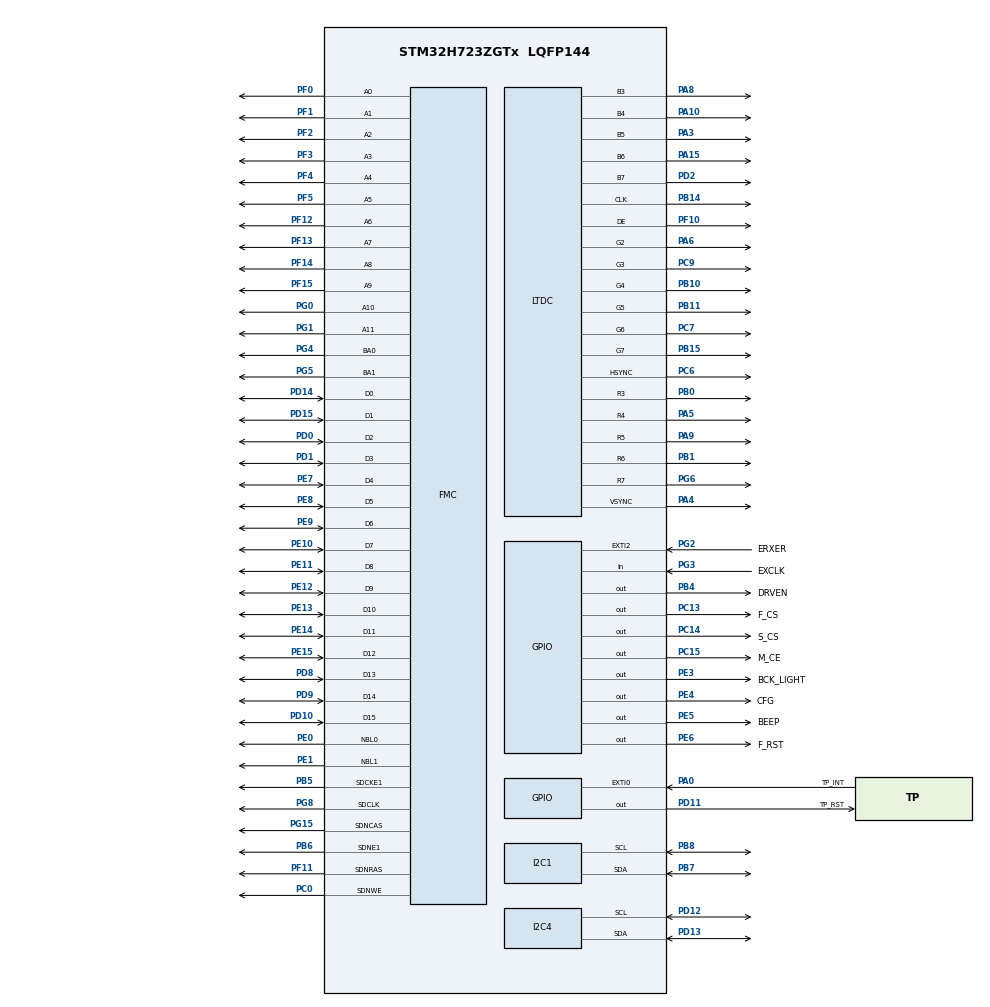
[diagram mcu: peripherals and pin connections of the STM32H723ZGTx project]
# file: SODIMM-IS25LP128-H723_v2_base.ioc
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CORTEX_M7.BaseAddress_S-Cortex_Memory_Protection_Unit_Region1_Settings_S=0x0
CORTEX_M7.BaseAddress_Spec=0xD0000000
CORTEX_M7.Enable_S-Cortex_Memory_Protection_Unit_Region1_Settings_S=__NULL
CORTEX_M7.IsCacheable_Spec=MPU_ACCESS_CACHEABLE
CORTEX_M7.IsShareable_Spec=MPU_ACCESS_NOT_SHAREABLE
CORTEX_M7.Size_S-Cortex_Memory_Protection_Unit_Region1_Settings_S=MPU_REGION_SIZE_8MB
CORTEX_M7.Size_Spec=MPU_REGION_SIZE_8MB
CORTEX_M7.SubRegionDisable_Spec=0x00
CORTEX_M7.default_mode_Activation=0
FMC.BankMapConfig=FMC_SWAPBMAP_DISABLE
FMC.CASLatency1=FMC_SDRAM_CAS_LATENCY_2
FMC.ExitSelfRefreshDelay1=7
FMC.LoadToActiveDelay1=2
FMC.RCDDelay1=2
FMC.RPDelay1=2
FMC.ReadBurst1=FMC_SDRAM_RBURST_ENABLE
FMC.ReadPipeDelay1=FMC_SDRAM_RPIPE_DELAY_2
FMC.RowCycleDelay1=6
FMC.SDClockPeriod1=FMC_SDRAM_CLOCK_PERIOD_2
FMC.SelfRefreshTime1=5
FMC.WriteRecoveryTime1=3
FREERTOS.Tasks01=defaultTask,0,128,StartDefaultTask,Default,NULL,Dynamic,NULL,NULL
I2C1.Timing=0x00000E14
I2C4.Timing=0x00000E14
LTDC.ActiveH=480
LTDC.ActiveW=800
LTDC.Alpha0_L0=0
LTDC.Alpha_L0=255
LTDC.Blue=0
LTDC.Blue_L0=0
LTDC.FBStartAdress_L0=0xD0000000
LTDC.Green=0
LTDC.Green_L0=0
LTDC.HBP=10
LTDC.HFP=10
LTDC.HSPolarity=LTDC_HSPOLARITY_AL
LTDC.HSync=10
LTDC.ImageHeight_L0=480
LTDC.ImageWidth_L0=800
LTDC.Layers=0
LTDC.PixelFormat_L0=LTDC_PIXEL_FORMAT_RGB565
LTDC.Red=0
LTDC.Red_L0=0
LTDC.VBP=2
LTDC.VFP=4
LTDC.VSync=2
LTDC.WindowX0_L0=0
LTDC.WindowX1_L0=800
LTDC.WindowY1_L0=480
Mcu.Family=STM32H7
Mcu.Name=STM32H723ZGTx
Mcu.Package=LQFP144
NVIC.LTDC_ER_IRQn=true\:5\:0\:false\:false\:true\:true\:true\:true\:true
NVIC.LTDC_IRQn=true\:5\:0\:false\:false\:true\:true\:true\:true\:true
NVIC.PriorityGroup=NVIC_PRIORITYGROUP_4
NVIC.TIM17_IRQn=true\:15\:0\:false\:false\:true\:false\:false\:true\:true
NVIC.TimeBase=TIM17_IRQn
NVIC.TimeBaseIP=TIM17
PA0.GPIO_Label=TP_INT
PA0.Signal=GPXTI0
PA10.Mode=RGB565
PA10.Signal=LTDC_B4
PA13(JTMS/SWDIO).Mode=Serial_Wire
PA13(JTMS/SWDIO).Signal=DEBUG_JTMS-SWDIO
PA14(JTCK/SWCLK).Mode=Serial_Wire
PA14(JTCK/SWCLK).Signal=DEBUG_JTCK-SWCLK
PA15(JTDI).Mode=RGB565
PA15(JTDI).Signal=LTDC_B6
PA3.Mode=RGB565
PA3.Signal=LTDC_B5
PA4.GPIO_Speed=GPIO_SPEED_FREQ_VERY_HIGH
PA4.Mode=RGB565
PA4.Signal=LTDC_VSYNC
PA5.Mode=RGB565
PA5.Signal=LTDC_R4
PA6.Mode=RGB565
PA6.Signal=LTDC_G2
PA8.Mode=RGB565
PA8.Signal=LTDC_B3
PA9.Mode=RGB565
PA9.Signal=LTDC_R5
PB0.Mode=RGB565
PB0.Signal=LTDC_R3
PB1.Mode=RGB565
PB1.Signal=LTDC_R6
PB10.Mode=RGB565
PB10.Signal=LTDC_G4
PB11.Mode=RGB565
PB11.Signal=LTDC_G5
PB14.GPIO_Speed=GPIO_SPEED_FREQ_VERY_HIGH
PB14.Mode=RGB565
PB14.Signal=LTDC_CLK
PB15.Mode=RGB565
PB15.Signal=LTDC_G7
PB4(NJTRST).GPIO_Label=DRVEN
PB4(NJTRST).Signal=GPIO_Output
PB5.Mode=SdramChipSelect2_1
PB5.Signal=FMC_SDCKE1
PB6.Mode=SdramChipSelect2_1
PB6.Signal=FMC_SDNE1
PB7.Mode=I2C
PB7.Signal=I2C1_SDA
PB8.Mode=I2C
PB8.Signal=I2C1_SCL
PC0.Signal=FMC_SDNWE
PC13.GPIO_Label=F_CS
PC13.Signal=GPIO_Output
PC14-OSC32_IN.GPIO_Label=S_CS
PC14-OSC32_IN.Signal=GPIO_Output
PC15-OSC32_OUT.GPIO_Label=M_CE
PC15-OSC32_OUT.Signal=GPIO_Output
PC6.GPIO_Speed=GPIO_SPEED_FREQ_VERY_HIGH
PC6.Mode=RGB565
PC6.Signal=LTDC_HSYNC
PC7.Mode=RGB565
PC7.Signal=LTDC_G6
PC9.Mode=RGB565
PC9.Signal=LTDC_G3
PD0.Signal=FMC_D2_DA2
PD1.Signal=FMC_D3_DA3
PD10.Signal=FMC_D15_DA15
PD11.GPIO_Label=TP_RST
PD11.Signal=GPIO_Output
PD12.Mode=I2C
PD12.Signal=I2C4_SCL
PD13.Mode=I2C
PD13.Signal=I2C4_SDA
PD14.Signal=FMC_D0_DA0
PD15.Signal=FMC_D1_DA1
PD2.Mode=RGB565
PD2.Signal=LTDC_B7
PD8.Signal=FMC_D13_DA13
PD9.Signal=FMC_D14_DA14
PE0.Signal=FMC_NBL0
PE1.Signal=FMC_NBL1
PE10.Signal=FMC_D7_DA7
PE11.Signal=FMC_D8_DA8
PE12.Signal=FMC_D9_DA9
PE13.Signal=FMC_D10_DA10
PE14.Signal=FMC_D11_DA11
PE15.Signal=FMC_D12_DA12
PE3.GPIO_Label=BCK_LIGHT
PE3.PinState=GPIO_PIN_SET
PE3.Signal=GPIO_Output
PE4.GPIO_Label=CFG
PE4.Signal=GPIO_Output
PE5.GPIO_Label=BEEP
PE5.Signal=GPIO_Output
PE6.GPIO_Label=F_RST
PE6.Signal=GPIO_Output
PE7.Signal=FMC_D4_DA4
PE8.Signal=FMC_D5_DA5
PE9.Signal=FMC_D6_DA6
PF0.Signal=FMC_A0
PF1.Signal=FMC_A1
PF10.Mode=RGB565
PF10.Signal=LTDC_DE
PF11.Signal=FMC_SDNRAS
PF12.Signal=FMC_A6
PF13.Signal=FMC_A7
PF14.Signal=FMC_A8
PF15.Signal=FMC_A9
PF2.Signal=FMC_A2
PF3.Signal=FMC_A3
PF4.Signal=FMC_A4
PF5.Signal=FMC_A5
PG0.Signal=FMC_A10
PG1.Signal=FMC_A11
PG15.Signal=FMC_SDNCAS
PG2.GPIO_Label=ERXER
PG2.Signal=GPXTI2
PG3.GPIO_Label=EXCLK
PG3.Signal=GPIO_Input
PG4.Signal=FMC_A14_BA0
PG5.Signal=FMC_A15_BA1
PG6.Mode=RGB565
PG6.Signal=LTDC_R7
PG8.Signal=FMC_SDCLK
PH0-OSC_IN.Mode=HSE-External-Oscillator
PH0-OSC_IN.Signal=RCC_OSC_IN
PH1-OSC_OUT.Mode=HSE-External-Oscillator
PH1-OSC_OUT.Signal=RCC_OSC_OUT
ProjectManager.HeapSize=0x200
ProjectManager.StackSize=0x400
ProjectManager.TargetToolchain=STM32CubeIDE
RCC.ADCFreq_Value=200000000
RCC.APB1Freq_Value=137000000
RCC.APB2Freq_Value=137000000
RCC.APB3Freq_Value=137000000
RCC.APB4Freq_Value=137000000
RCC.CKPERSourceSelection=RCC_CLKPSOURCE_HSE
RCC.CortexFreq_Value=548000000
RCC.D1PPRE=RCC_APB3_DIV2
RCC.D2PPRE1=RCC_APB1_DIV2
RCC.D2PPRE2=RCC_APB2_DIV2
RCC.D3PPRE=RCC_APB4_DIV2
RCC.DIVM1=1
RCC.DIVM2=2
RCC.DIVM3=1
RCC.DIVN1=137
RCC.DIVN2=200
RCC.DIVN3=24
RCC.DIVP1=1
RCC.DIVP3=4
RCC.DIVQ1=5
RCC.DIVQ2=20
RCC.DIVQ3=8
RCC.DIVR1=1
RCC.DIVR3=3
RCC.FDCANCLockSelection=RCC_FDCANCLKSOURCE_PLL2
RCC.FMCCLockSelection=RCC_FMCCLKSOURCE_PLL2
RCC.HCLKFreq_Value=274000000
RCC.HPRE=RCC_HCLK_DIV2
RCC.HSE_VALUE=8000000
RCC.I2C123CLockSelection=RCC_I2C1235CLKSOURCE_CSI
RCC.I2C4CLockSelection=RCC_I2C4CLKSOURCE_CSI
RCC.PLL2FRACN=0
RCC.PLL3FRACN=0
RCC.PLLFRACN=0
RCC.PLLSourceVirtual=RCC_PLLSOURCE_CSI
RCC.QSPICLockSelection=RCC_OSPICLKSOURCE_PLL
RCC.SPI123CLockSelection=RCC_SPI123CLKSOURCE_CLKP
RCC.SYSCLKFreq_VALUE=548000000
RCC.SYSCLKSource=RCC_SYSCLKSOURCE_PLLCLK
RCC.SupplySource=PWR_LDO_SUPPLY
RCC.USART234578CLockSelection=RCC_USART234578CLKSOURCE_HSI
RCC.USBCLockSelection=RCC_USBCLKSOURCE_HSI48
RCC.USBFreq_Value=48000000
RCC.VDD_VALUE=3.2
SH.FMC_A0.0=FMC_A0,12b-sda1
SH.FMC_A1.0=FMC_A1,12b-sda1
SH.FMC_A10.0=FMC_A10,12b-sda1
SH.FMC_A11.0=FMC_A11,12b-sda1
SH.FMC_A14_BA0.0=FMC_BA0,FourSdramBanks1
SH.FMC_A15_BA1.0=FMC_BA1,FourSdramBanks1
SH.FMC_A2.0=FMC_A2,12b-sda1
SH.FMC_A3.0=FMC_A3,12b-sda1
SH.FMC_A4.0=FMC_A4,12b-sda1
SH.FMC_A5.0=FMC_A5,12b-sda1
SH.FMC_A6.0=FMC_A6,12b-sda1
SH.FMC_A7.0=FMC_A7,12b-sda1
SH.FMC_A8.0=FMC_A8,12b-sda1
SH.FMC_A9.0=FMC_A9,12b-sda1
SH.FMC_D0_DA0.0=FMC_D0,sd-16b-d1
SH.FMC_D10_DA10.0=FMC_D10,sd-16b-d1
SH.FMC_D11_DA11.0=FMC_D11,sd-16b-d1
SH.FMC_D12_DA12.0=FMC_D12,sd-16b-d1
SH.FMC_D13_DA13.0=FMC_D13,sd-16b-d1
SH.FMC_D14_DA14.0=FMC_D14,sd-16b-d1
SH.FMC_D15_DA15.0=FMC_D15,sd-16b-d1
SH.FMC_D1_DA1.0=FMC_D1,sd-16b-d1
SH.FMC_D2_DA2.0=FMC_D2,sd-16b-d1
SH.FMC_D3_DA3.0=FMC_D3,sd-16b-d1
SH.FMC_D4_DA4.0=FMC_D4,sd-16b-d1
SH.FMC_D5_DA5.0=FMC_D5,sd-16b-d1
SH.FMC_D6_DA6.0=FMC_D6,sd-16b-d1
SH.FMC_D7_DA7.0=FMC_D7,sd-16b-d1
SH.FMC_D8_DA8.0=FMC_D8,sd-16b-d1
SH.FMC_D9_DA9.0=FMC_D9,sd-16b-d1
SH.FMC_NBL0.0=FMC_NBL0,Sd2ByteEnable1
SH.FMC_NBL1.0=FMC_NBL1,Sd2ByteEnable1
SH.FMC_SDCLK.0=FMC_SDCLK,12b-sda1
SH.FMC_SDNCAS.0=FMC_SDNCAS,12b-sda1
SH.FMC_SDNRAS.0=FMC_SDNRAS,12b-sda1
SH.FMC_SDNWE.0=FMC_SDNWE,12b-sda1
STMicroelectronics.X-CUBE-TOUCHGFX.4.20.0.ApplicationCcGraphicsJjApplication=TouchGFXOoGenerator
STMicroelectronics.X-CUBE-TOUCHGFX.4.20.0.tgfx_address1=0xD0000000
STMicroelectronics.X-CUBE-TOUCHGFX.4.20.0.tgfx_address2=0xD0010000
STMicroelectronics.X-CUBE-TOUCHGFX.4.20.0.tgfx_buffering_strategy=Single
STMicroelectronics.X-CUBE-TOUCHGFX.4.20.0.tgfx_custom_height=480
STMicroelectronics.X-CUBE-TOUCHGFX.4.20.0.tgfx_display_interface=disp_ltdc
STMicroelectronics.X-CUBE-TOUCHGFX.4.20.0.tgfx_hardware_accelerator=dma_none
STMicroelectronics.X-CUBE-TOUCHGFX.4.20.0.tgfx_location=By Address
STMicroelectronics.X-CUBE-TOUCHGFX.4.20.0.tgfx_vsync=vsync_ltdc
STMicroelectronics.X-CUBE-TOUCHGFX.4.20.0_IsPackSelfContextualization=true
VP_CRC_VS_CRC.Mode=CRC_Activate
VP_FREERTOS_VS_CMSIS_V1.Mode=CMSIS_V1
VP_STMicroelectronics.X-CUBE-TOUCHGFX_VS_GraphicsJjApplication_4.20.0.Mode=GraphicsJjApplication
VP_SYS_VS_tim17.Mode=TIM17
board=custom

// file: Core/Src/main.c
/* USER CODE BEGIN Header */
/**
  ******************************************************************************
  * @file           : main.c
  * @brief          : Main program body
  ******************************************************************************
  * @attention
  *
  * Copyright (c) 2022 STMicroelectronics.
  * All rights reserved.
  *
  * This software is licensed under terms that can be found in the LICENSE file
  * in the root directory of this software component.
  * If no LICENSE file comes with this software, it is provided AS-IS.
  *
  ******************************************************************************
  */
/* USER CODE END Header */
#include "main.h"
#include "cmsis_os.h"
#include "app_touchgfx.h"

/* USER CODE BEGIN Includes */
//uint16_t* frame_buffer = (uint16_t*) 0xD0000000;

#define SDRAM_BANK_ADDR                 ((uint32_t)0xD0000000)

/* #define SDRAM_MEMORY_WIDTH            FMC_SDMemory_Width_8b  */
#define SDRAM_MEMORY_WIDTH            FMC_SDMemory_Width_16b
//uint32_t FrontBuffer = SDRAM_BANK_ADDR;
volatile uint16_t temp[10];
//__attribute__((section(".sdram"))) uint32_t framebuffer[];

#define SDRAM_MODEREG_BURST_LENGTH_1             ((uint16_t)0x0000)
#define SDRAM_MODEREG_BURST_LENGTH_2             ((uint16_t)0x0001)
#define SDRAM_MODEREG_BURST_LENGTH_4             ((uint16_t)0x0002)
#define SDRAM_MODEREG_BURST_LENGTH_8             ((uint16_t)0x0003)
#define SDRAM_MODEREG_BURST_TYPE_SEQUENTIAL      ((uint16_t)0x0000)
#define SDRAM_MODEREG_BURST_TYPE_INTERLEAVED     ((uint16_t)0x0008)
#define SDRAM_MODEREG_CAS_LATENCY_2              ((uint16_t)0x0020)
#define SDRAM_MODEREG_CAS_LATENCY_3              ((uint16_t)0x0030)
#define SDRAM_MODEREG_OPERATING_MODE_STANDARD    ((uint16_t)0x0000)
#define SDRAM_MODEREG_WRITEBURST_MODE_PROGRAMMED ((uint16_t)0x0000)
#define SDRAM_MODEREG_WRITEBURST_MODE_SINGLE     ((uint16_t)0x0200)

#define SDRAM_REFRESH_COUNT                   	 ((uint32_t)4096)

/* USER CODE END Includes */

/* USER CODE BEGIN PTD */

	// Assign SDRAM address to pointer

/* USER CODE END PTD */

CRC_HandleTypeDef hcrc;

I2C_HandleTypeDef hi2c1;
I2C_HandleTypeDef hi2c4;

LTDC_HandleTypeDef hltdc;

SDRAM_HandleTypeDef hsdram1;

osThreadId defaultTaskHandle;

void SystemClock_Config(void);
static void MX_GPIO_Init(void);
static void MX_FMC_Init(void);
static void MX_I2C1_Init(void);
static void MX_I2C4_Init(void);
static void MX_LTDC_Init(void);
static void MX_CRC_Init(void);
void StartDefaultTask(void const * argument);

int main(void)
{
  /* USER CODE BEGIN 1 */

	  MPU->RNR = 1;

	  //External Ram base address
	  MPU->RBAR = 0xD0000000;

	  //XN=Disabled, AP=Full Access, TEX=Level 2, S=Not Shareable, C=Not Cacheable, B=Not bufferable, SRB=Disabled, Size=8MB, Enable=1
	  MPU->RASR = (1 << MPU_RASR_XN_Pos) |
	         (3 << MPU_RASR_AP_Pos) |
	        (2 << MPU_RASR_TEX_Pos) |
	        (0 << MPU_RASR_S_Pos) |
	        (0 << MPU_RASR_C_Pos) |
	        (0 << MPU_RASR_B_Pos) |
	        (1 << MPU_RASR_SRD_Pos) |
	        (0x16 << MPU_RASR_SIZE_Pos) |
	        (1 << MPU_RASR_ENABLE_Pos);

  /* USER CODE END 1 */

  /* MCU Configuration--------------------------------------------------------*/

  /* Reset of all peripherals, Initializes the Flash interface and the Systick. */
  HAL_Init();

  /* Configure the system clock */
  SystemClock_Config();

  /* Initialize all configured peripherals */
  MX_GPIO_Init();
  MX_FMC_Init();
  MX_I2C1_Init();
  MX_I2C4_Init();
  MX_LTDC_Init();
  MX_CRC_Init();
  MX_TouchGFX_Init();
  /* Call PreOsInit function */
  MX_TouchGFX_PreOSInit();

  /* Create the thread(s) */
  /* definition and creation of defaultTask */
  osThreadDef(defaultTask, StartDefaultTask, osPriorityNormal, 0, 128);
  defaultTaskHandle = osThreadCreate(osThread(defaultTask), NULL);

  /* Start scheduler */
  osKernelStart();

  /* We should never get here as control is now taken by the scheduler */
  /* Infinite loop */
  while (1)
  {

  }
}

void SystemClock_Config(void)
{
  RCC_OscInitTypeDef RCC_OscInitStruct = {0};
  RCC_ClkInitTypeDef RCC_ClkInitStruct = {0};

  /** Supply configuration update enable
  */
  HAL_PWREx_ConfigSupply(PWR_LDO_SUPPLY);

  /** Configure the main internal regulator output voltage
  */
  __HAL_PWR_VOLTAGESCALING_CONFIG(PWR_REGULATOR_VOLTAGE_SCALE0);

  while(!__HAL_PWR_GET_FLAG(PWR_FLAG_VOSRDY)) {}

  /** Macro to configure the PLL clock source
  */
  __HAL_RCC_PLL_PLLSOURCE_CONFIG(RCC_PLLSOURCE_CSI);

  /** Initializes the RCC Oscillators according to the specified parameters
  * in the RCC_OscInitTypeDef structure.
  */
  RCC_OscInitStruct.OscillatorType = RCC_OSCILLATORTYPE_CSI;
  RCC_OscInitStruct.CSIState = RCC_CSI_ON;
  RCC_OscInitStruct.CSICalibrationValue = 16;
  RCC_OscInitStruct.PLL.PLLState = RCC_PLL_ON;
  RCC_OscInitStruct.PLL.PLLSource = RCC_PLLSOURCE_CSI;
  RCC_OscInitStruct.PLL.PLLM = 1;
  RCC_OscInitStruct.PLL.PLLN = 137;
  RCC_OscInitStruct.PLL.PLLP = 1;
  RCC_OscInitStruct.PLL.PLLQ = 5;
  RCC_OscInitStruct.PLL.PLLR = 1;
  RCC_OscInitStruct.PLL.PLLRGE = RCC_PLL1VCIRANGE_2;
  RCC_OscInitStruct.PLL.PLLVCOSEL = RCC_PLL1VCOWIDE;
  RCC_OscInitStruct.PLL.PLLFRACN = 0;
  if (HAL_RCC_OscConfig(&RCC_OscInitStruct) != HAL_OK)
  {
    Error_Handler();
  }

  /** Initializes the CPU, AHB and APB buses clocks
  */
  RCC_ClkInitStruct.ClockType = RCC_CLOCKTYPE_HCLK|RCC_CLOCKTYPE_SYSCLK
                              |RCC_CLOCKTYPE_PCLK1|RCC_CLOCKTYPE_PCLK2
                              |RCC_CLOCKTYPE_D3PCLK1|RCC_CLOCKTYPE_D1PCLK1;
  RCC_ClkInitStruct.SYSCLKSource = RCC_SYSCLKSOURCE_PLLCLK;
  RCC_ClkInitStruct.SYSCLKDivider = RCC_SYSCLK_DIV1;
  RCC_ClkInitStruct.AHBCLKDivider = RCC_HCLK_DIV2;
  RCC_ClkInitStruct.APB3CLKDivider = RCC_APB3_DIV2;
  RCC_ClkInitStruct.APB1CLKDivider = RCC_APB1_DIV2;
  RCC_ClkInitStruct.APB2CLKDivider = RCC_APB2_DIV2;
  RCC_ClkInitStruct.APB4CLKDivider = RCC_APB4_DIV2;

  if (HAL_RCC_ClockConfig(&RCC_ClkInitStruct, FLASH_LATENCY_3) != HAL_OK)
  {
    Error_Handler();
  }
}

static void MX_CRC_Init(void)
{

  hcrc.Instance = CRC;
  hcrc.Init.DefaultPolynomialUse = DEFAULT_POLYNOMIAL_ENABLE;
  hcrc.Init.DefaultInitValueUse = DEFAULT_INIT_VALUE_ENABLE;
  hcrc.Init.InputDataInversionMode = CRC_INPUTDATA_INVERSION_NONE;
  hcrc.Init.OutputDataInversionMode = CRC_OUTPUTDATA_INVERSION_DISABLE;
  hcrc.InputDataFormat = CRC_INPUTDATA_FORMAT_BYTES;
  if (HAL_CRC_Init(&hcrc) != HAL_OK)
  {
    Error_Handler();
  }

}

static void MX_I2C1_Init(void)
{

  hi2c1.Instance = I2C1;
  hi2c1.Init.Timing = 0x00000E14;
  hi2c1.Init.OwnAddress1 = 0;
  hi2c1.Init.AddressingMode = I2C_ADDRESSINGMODE_7BIT;
  hi2c1.Init.DualAddressMode = I2C_DUALADDRESS_DISABLE;
  hi2c1.Init.OwnAddress2 = 0;
  hi2c1.Init.OwnAddress2Masks = I2C_OA2_NOMASK;
  hi2c1.Init.GeneralCallMode = I2C_GENERALCALL_DISABLE;
  hi2c1.Init.NoStretchMode = I2C_NOSTRETCH_DISABLE;
  if (HAL_I2C_Init(&hi2c1) != HAL_OK)
  {
    Error_Handler();
  }

  /** Configure Analogue filter
  */
  if (HAL_I2CEx_ConfigAnalogFilter(&hi2c1, I2C_ANALOGFILTER_ENABLE) != HAL_OK)
  {
    Error_Handler();
  }

  /** Configure Digital filter
  */
  if (HAL_I2CEx_ConfigDigitalFilter(&hi2c1, 0) != HAL_OK)
  {
    Error_Handler();
  }

}

static void MX_I2C4_Init(void)
{

  hi2c4.Instance = I2C4;
  hi2c4.Init.Timing = 0x00000E14;
  hi2c4.Init.OwnAddress1 = 0;
  hi2c4.Init.AddressingMode = I2C_ADDRESSINGMODE_7BIT;
  hi2c4.Init.DualAddressMode = I2C_DUALADDRESS_DISABLE;
  hi2c4.Init.OwnAddress2 = 0;
  hi2c4.Init.OwnAddress2Masks = I2C_OA2_NOMASK;
  hi2c4.Init.GeneralCallMode = I2C_GENERALCALL_DISABLE;
  hi2c4.Init.NoStretchMode = I2C_NOSTRETCH_DISABLE;
  if (HAL_I2C_Init(&hi2c4) != HAL_OK)
  {
    Error_Handler();
  }

  /** Configure Analogue filter
  */
  if (HAL_I2CEx_ConfigAnalogFilter(&hi2c4, I2C_ANALOGFILTER_ENABLE) != HAL_OK)
  {
    Error_Handler();
  }

  /** Configure Digital filter
  */
  if (HAL_I2CEx_ConfigDigitalFilter(&hi2c4, 0) != HAL_OK)
  {
    Error_Handler();
  }

}

static void MX_LTDC_Init(void)
{

  LTDC_LayerCfgTypeDef pLayerCfg = {0};

  hltdc.Instance = LTDC;
  hltdc.Init.HSPolarity = LTDC_HSPOLARITY_AL;
  hltdc.Init.VSPolarity = LTDC_VSPOLARITY_AL;
  hltdc.Init.DEPolarity = LTDC_DEPOLARITY_AL;
  hltdc.Init.PCPolarity = LTDC_PCPOLARITY_IPC;
  hltdc.Init.HorizontalSync = 9;
  hltdc.Init.VerticalSync = 1;
  hltdc.Init.AccumulatedHBP = 19;
  hltdc.Init.AccumulatedVBP = 3;
  hltdc.Init.AccumulatedActiveW = 819;
  hltdc.Init.AccumulatedActiveH = 483;
  hltdc.Init.TotalWidth = 829;
  hltdc.Init.TotalHeigh = 487;
  hltdc.Init.Backcolor.Blue = 0;
  hltdc.Init.Backcolor.Green = 0;
  hltdc.Init.Backcolor.Red = 0;
  if (HAL_LTDC_Init(&hltdc) != HAL_OK)
  {
    Error_Handler();
  }
  pLayerCfg.WindowX0 = 0;
  pLayerCfg.WindowX1 = 800;
  pLayerCfg.WindowY0 = 0;
  pLayerCfg.WindowY1 = 480;
  pLayerCfg.PixelFormat = LTDC_PIXEL_FORMAT_RGB565;
  pLayerCfg.Alpha = 255;
  pLayerCfg.Alpha0 = 0;
  pLayerCfg.BlendingFactor1 = LTDC_BLENDING_FACTOR1_CA;
  pLayerCfg.BlendingFactor2 = LTDC_BLENDING_FACTOR2_CA;
  pLayerCfg.FBStartAdress = 0xD0000000;
  pLayerCfg.ImageWidth = 800;
  pLayerCfg.ImageHeight = 480;
  pLayerCfg.Backcolor.Blue = 0;
  pLayerCfg.Backcolor.Green = 0;
  pLayerCfg.Backcolor.Red = 0;
  if (HAL_LTDC_ConfigLayer(&hltdc, &pLayerCfg, 0) != HAL_OK)
  {
    Error_Handler();
  }
  /* USER CODE BEGIN LTDC_Init 2 */

	 // HAL_LTDC_SetAddress(&hltdc, 0xD0000000, 0);
  /* USER CODE END LTDC_Init 2 */

}

/* FMC initialization function */
static void MX_FMC_Init(void)
{

  FMC_SDRAM_TimingTypeDef SdramTiming = {0};

  /** Perform the SDRAM1 memory initialization sequence
  */
  hsdram1.Instance = FMC_SDRAM_DEVICE;
  /* hsdram1.Init */
  hsdram1.Init.SDBank = FMC_SDRAM_BANK2;
  hsdram1.Init.ColumnBitsNumber = FMC_SDRAM_COLUMN_BITS_NUM_8;
  hsdram1.Init.RowBitsNumber = FMC_SDRAM_ROW_BITS_NUM_12;
  hsdram1.Init.MemoryDataWidth = FMC_SDRAM_MEM_BUS_WIDTH_16;
  hsdram1.Init.InternalBankNumber = FMC_SDRAM_INTERN_BANKS_NUM_4;
  hsdram1.Init.CASLatency = FMC_SDRAM_CAS_LATENCY_2;
  hsdram1.Init.WriteProtection = FMC_SDRAM_WRITE_PROTECTION_DISABLE;
  hsdram1.Init.SDClockPeriod = FMC_SDRAM_CLOCK_PERIOD_2;
  hsdram1.Init.ReadBurst = FMC_SDRAM_RBURST_ENABLE;
  hsdram1.Init.ReadPipeDelay = FMC_SDRAM_RPIPE_DELAY_2;
  /* SdramTiming */
  SdramTiming.LoadToActiveDelay = 2;
  SdramTiming.ExitSelfRefreshDelay = 7;
  SdramTiming.SelfRefreshTime = 5;
  SdramTiming.RowCycleDelay = 6;
  SdramTiming.WriteRecoveryTime = 3;
  SdramTiming.RPDelay = 2;
  SdramTiming.RCDDelay = 2;

  if (HAL_SDRAM_Init(&hsdram1, &SdramTiming) != HAL_OK)
  {
    Error_Handler( );
  }

  /* USER CODE BEGIN FMC_Init 2 */

  HAL_Delay(10);

  FMC_SDRAM_CommandTypeDef Command;
  // Step 1 and Step 2 already done in HAL_SDRAM_Init() //
  // Step 3: Configure a clock configuration enable command //
   Command.CommandMode            = FMC_SDRAM_CMD_CLK_ENABLE; // Set MODE bits to "001" //
   Command.CommandTarget          = FMC_SDRAM_CMD_TARGET_BANK2; // configure the Target Bank bits //
   Command.AutoRefreshNumber      = 1;
   Command.ModeRegisterDefinition = 0;
   HAL_SDRAM_SendCommand(&hsdram1, &Command, 0xfff);
   HAL_Delay(1); // Step 4: Insert 100 us minimum delay - Min HAL Delay is 1ms //
   // Step 5: Configure a PALL (precharge all) command //
   Command.CommandMode            = FMC_SDRAM_CMD_PALL; // Set MODE bits to "010" //
   HAL_SDRAM_SendCommand(&hsdram1, &Command, 0xfff);
   // Step 6: Configure an Auto Refresh command //
   Command.CommandMode            = FMC_SDRAM_CMD_AUTOREFRESH_MODE; // Set MODE bits to "011" //
   Command.AutoRefreshNumber      = 2;
   HAL_SDRAM_SendCommand(&hsdram1, &Command, 0xfff);
   // Step 7: Program the external memory mode register //
   Command.CommandMode            = FMC_SDRAM_CMD_LOAD_MODE;//set the MODE bits to "100" //
   Command.ModeRegisterDefinition =  (uint32_t)0 | 0<<3 | 2<<4 | 0<<7 | 1<<9;
   HAL_SDRAM_SendCommand(&hsdram1, &Command, 0xfff);
   // Step 8: Set the refresh rate counter - refer to section SDRAM refresh timer register in RM0455
   // Set the device refresh rate
    // COUNT = [(SDRAM self refresh time / number of row) x  SDRAM CLK] – 20
    //        = [(64ms/4096) * 100MHz] - 20 = 1562.5 - 20 ~ 1542
   HAL_SDRAM_ProgramRefreshRate(&hsdram1, 1542);

  /* USER CODE END FMC_Init 2 */
}

static void MX_GPIO_Init(void)
{
  GPIO_InitTypeDef GPIO_InitStruct = {0};

  /* GPIO Ports Clock Enable */
  __HAL_RCC_GPIOE_CLK_ENABLE();
  __HAL_RCC_GPIOC_CLK_ENABLE();
  __HAL_RCC_GPIOF_CLK_ENABLE();
  __HAL_RCC_GPIOH_CLK_ENABLE();
  __HAL_RCC_GPIOA_CLK_ENABLE();
  __HAL_RCC_GPIOB_CLK_ENABLE();
  __HAL_RCC_GPIOG_CLK_ENABLE();
  __HAL_RCC_GPIOD_CLK_ENABLE();

  /*Configure GPIO pin Output Level */
  HAL_GPIO_WritePin(BCK_LIGHT_GPIO_Port, BCK_LIGHT_Pin, GPIO_PIN_SET);

  /*Configure GPIO pin Output Level */
  HAL_GPIO_WritePin(GPIOE, CFG_Pin|BEEP_Pin|F_RST_Pin, GPIO_PIN_RESET);

  /*Configure GPIO pin Output Level */
  HAL_GPIO_WritePin(GPIOC, F_CS_Pin|S_CS_Pin|M_CE_Pin, GPIO_PIN_RESET);

  /*Configure GPIO pin Output Level */
  HAL_GPIO_WritePin(TP_RST_GPIO_Port, TP_RST_Pin, GPIO_PIN_RESET);

  /*Configure GPIO pin Output Level */
  HAL_GPIO_WritePin(DRVEN_GPIO_Port, DRVEN_Pin, GPIO_PIN_RESET);

  /*Configure GPIO pins : BCK_LIGHT_Pin CFG_Pin BEEP_Pin F_RST_Pin */
  GPIO_InitStruct.Pin = BCK_LIGHT_Pin|CFG_Pin|BEEP_Pin|F_RST_Pin;
  GPIO_InitStruct.Mode = GPIO_MODE_OUTPUT_PP;
  GPIO_InitStruct.Pull = GPIO_NOPULL;
  GPIO_InitStruct.Speed = GPIO_SPEED_FREQ_LOW;
  HAL_GPIO_Init(GPIOE, &GPIO_InitStruct);

  /*Configure GPIO pins : F_CS_Pin S_CS_Pin M_CE_Pin */
  GPIO_InitStruct.Pin = F_CS_Pin|S_CS_Pin|M_CE_Pin;
  GPIO_InitStruct.Mode = GPIO_MODE_OUTPUT_PP;
  GPIO_InitStruct.Pull = GPIO_NOPULL;
  GPIO_InitStruct.Speed = GPIO_SPEED_FREQ_LOW;
  HAL_GPIO_Init(GPIOC, &GPIO_InitStruct);

  /*Configure GPIO pin : TP_INT_Pin */
  GPIO_InitStruct.Pin = TP_INT_Pin;
  GPIO_InitStruct.Mode = GPIO_MODE_IT_RISING;
  GPIO_InitStruct.Pull = GPIO_NOPULL;
  HAL_GPIO_Init(TP_INT_GPIO_Port, &GPIO_InitStruct);

  /*Configure GPIO pin : TP_RST_Pin */
  GPIO_InitStruct.Pin = TP_RST_Pin;
  GPIO_InitStruct.Mode = GPIO_MODE_OUTPUT_PP;
  GPIO_InitStruct.Pull = GPIO_NOPULL;
  GPIO_InitStruct.Speed = GPIO_SPEED_FREQ_LOW;
  HAL_GPIO_Init(TP_RST_GPIO_Port, &GPIO_InitStruct);

  /*Configure GPIO pin : ERXER_Pin */
  GPIO_InitStruct.Pin = ERXER_Pin;
  GPIO_InitStruct.Mode = GPIO_MODE_IT_RISING;
  GPIO_InitStruct.Pull = GPIO_NOPULL;
  HAL_GPIO_Init(ERXER_GPIO_Port, &GPIO_InitStruct);

  /*Configure GPIO pin : EXCLK_Pin */
  GPIO_InitStruct.Pin = EXCLK_Pin;
  GPIO_InitStruct.Mode = GPIO_MODE_INPUT;
  GPIO_InitStruct.Pull = GPIO_NOPULL;
  HAL_GPIO_Init(EXCLK_GPIO_Port, &GPIO_InitStruct);

  /*Configure GPIO pin : DRVEN_Pin */
  GPIO_InitStruct.Pin = DRVEN_Pin;
  GPIO_InitStruct.Mode = GPIO_MODE_OUTPUT_PP;
  GPIO_InitStruct.Pull = GPIO_NOPULL;
  GPIO_InitStruct.Speed = GPIO_SPEED_FREQ_LOW;
  HAL_GPIO_Init(DRVEN_GPIO_Port, &GPIO_InitStruct);

}

void StartDefaultTask(void const * argument)
{
  /* USER CODE BEGIN 5 */

//	FMC_Bank1->BTCR[0] = 0x000030D2;

	//temp[0] = framebuffer[0];
	//temp[1] = framebuffer[16000];

	MX_TouchGFX_Init();
	MX_TouchGFX_Process();
  /* Infinite loop */

  for(;;)
  {

	/*
		uint32_t i = 1;
		uint32_t j = 0;

		uint16_t TxBuffer32[] = { 0x0123, 0x4567 };

		uint16_t RxBuffer32[2];

		*/
/*
		for (uint32_t k = 0; k < 768000; k++) {

				*(test32 + k) = l;

				temp = *(test32 + k);

				if( l != temp)
				{
				//l++;
				}
				else
				{
					//l = l;
				}

			}

			//l = l;

*/

		osDelay(100);
		//c++;

   //gg_temp = *(__IO uint32_t*)0xD0000100;

  }
  /* USER CODE END 5 */
}

void HAL_TIM_PeriodElapsedCallback(TIM_HandleTypeDef *htim)
{
  if (htim->Instance == TIM17) {
    HAL_IncTick();
  }
}

void Error_Handler(void)
{
  __disable_irq();
  while (1)
  {
  }
}
